# CLK3_STATCOLL_SDRAM register map
Vendor: Texas Instruments
Peripheral module from a debugger description file (folder omap4460).
Registers are 32-bit, access per field, reset 0x0 unless marked. A register's access mark holds for its fields unless they carry their own. Offsets are as the file gives them; lines under a group give offsets from that group; [hi:lo] are bit positions; {n}, {i} and the like mark numbered series; 'fields as' and 'values as' point back to an identical list; <NAME> marks a mode.

## CLK3_STATCOLL_SDRAM
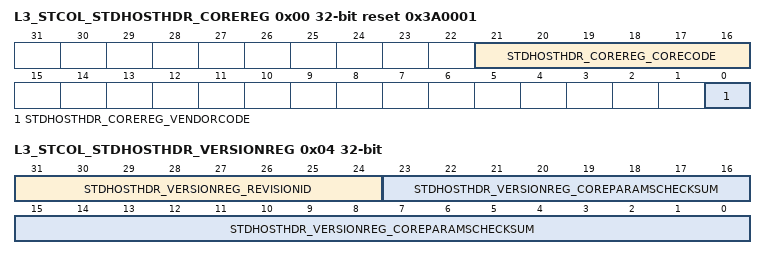
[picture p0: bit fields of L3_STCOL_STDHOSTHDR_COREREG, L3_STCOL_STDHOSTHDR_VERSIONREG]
0x00 L3_STCOL_STDHOSTHDR_COREREG ro reset 0x3A0001
  [21:16] STDHOSTHDR_COREREG_CORECODE — The Core Code field is a constant reporting a vendor-specific core generator code. Type: Constant. Reset value: 0x3A.
  [0] STDHOSTHDR_COREREG_VENDORCODE — The Vendor Code field is a constant reporting the core generator vendor code. Type: Constant. Reset value: 0x1.
    0=STDHOSTHDR_COREREG_VENDORCODE_0_r (Third-party vendor.); 1=STDHOSTHDR_COREREG_VENDORCODE_1_r
0x04 L3_STCOL_STDHOSTHDR_VERSIONREG ro
  [31:24] STDHOSTHDR_VERSIONREG_REVISIONID — The Revision Identifier field is a constant reporting the core generator revision number. Type: Constant. Reset value: 0x0.
  [23:0] STDHOSTHDR_VERSIONREG_COREPARAMSCHECKSUM — Reserved. Type: Reserved. Reset value: Reserved.
0x08 L3_STCOL_EN
  [0] EN rw — Enable performance monitoring, this will also shut down the clock if En = 0 Type: Control. Reset value: 0x0.
0x0C L3_STCOL_SOFTEN
  [0] SOFTEN rw — Software enable for performance monitoring Type: Control. Reset value: 0x0.
0x14 L3_STCOL_TRIGEN
  [0] TRIGEN rw — TrigEn when set, it enable the external trigger start and stop Type: Control. Reset value: 0x0.
0x18 L3_STCOL_REQEVT
  [3:0] REQEVT rw — Req event select Type: Control. Reset value: 0x0.
    0=Collect is disabled default value; 1=Collect all event: hit always (cycle); 2=Collect transfers: actually used cycle for transferring aN NTTP word; 3=Collect wait cycle: transfer has been delayed by source; 4=Collect busy: transfer has been delayed by destination; 5=Collect packet: new packet start; 6=Collect data: data cycle transfer, write for requests, read for responses; 7=Collect idles: transfer is not initiated by source; 8=Collect latency: hit when actually detecting debug bit on response links
0x1C L3_STCOL_RSPEVT
  [3:0] RSPEVT rw — Rsp event select Type: Control. Reset value: 0x0.
    0=Collect is disabled default value; 1=Collect all event: hit always (cycle); 2=Collect transfers: actually used cycle for transferring a NTTP word; 3=Collect wait cycle: transfer has been delayed by source; 4=Collect busy: transfer has been delayed by destination; 5=Collect packet: new packet start; 6=Collect data: data cycle transfer, write for requests, read for responses; 7=Collect idles: transfer is not initiated by source; 8=Collect latency: hit when actually detecting debug bit on response links
{0x20+4i} L3_STCOL_EVTMUX_SEL{i} (i=0..4)
  [2:0] EVTMUX_SEL{i} rw — The select of the mux {i} Type: Control. Reset value: 0x0.
0x40 L3_STCOL_DUMP_IDENTIFIER ro
  [1:0] DUMP_IDENTIFIER — Probe identifier Type: Control. Reset value: 0x0.
0x44 L3_STCOL_DUMP_COLLECTTIME
  [15:0] DUMP_COLLECTTIME rw — Number of cycle to wait between two statistics frame Type: Control. Reset value: 0x0.
0x48 L3_STCOL_DUMP_SLVADDR ro reset 0x19
  [4:0] DUMP_SLVADDR — Dump slave address Type: Control. Reset value: 0x19.
0x4C L3_STCOL_DUMP_MSTADDR ro reset 0xE0
  [7:0] DUMP_MSTADDR — Dump master address Type: Control. Reset value: 0xE0.
0x50 L3_STCOL_DUMP_SLVOFS rw reset 0x800
  [31:0] DUMP_SLVOFS — Dump slave offset Type: Control. Reset value: 0x800.
0x54 L3_STCOL_DUMP_MANUAL
  [0] DUMP_MANUAL rw — Define the dump mode: if != 0 the dump is controlled by the Send register. Type: Control. Reset value: 0x0.
0x58 L3_STCOL_DUMP_SEND
  [0] DUMP_SEND rw — In manual mode, is used to send the dump content and initialize the counters. Type: Give_AutoCleared. Reset value: 0x0.
0xAC L3_STCOL_FILTER_i_GLOBALEN
  [0] FILTER_i_GLOBALEN rw — Filter global enable Type: Control. Reset value: 0x0.
0xB0 L3_STCOL_FILTER_i_ADDRMIN
  [22:0] FILTER1_ADDRMIN rw — min addr range Type: Control. Reset value: 0x0.
0xB4 L3_STCOL_FILTER_i_ADDRMAX
  [22:0] FILTER1_ADDRMAX rw — max addr range Type: Control. Reset value: 0x0.
0xB8 L3_STCOL_FILTER_i_ADDREN
  [0] FILTER1_ADDREN rw — max filtering enable Type: Control. Reset value: 0x0.
0xBC L3_STCOL_FILTER_i_EN_k
  [0] FILTER_i_EN0 rw — Enable filter stage 0 Type: Control. Reset value: 0x0.
0xC0 L3_STCOL_FILTER_i_MASK_m_RD
  [0] FILTER_i_MASK_m_RD rw — Mask/Match of Rd Type: Control. Reset value: 0x0.
0xC4 L3_STCOL_FILTER_i_MASK_m_WR
  [0] FILTER_i_MASK_m_WR rw — Mask/Match of Wr Type: Control. Reset value: 0x0.
0xC8 L3_STCOL_FILTER_i_MASK_m_MSTADDR
  [7:0] FILTER_i_MASK_m_MSTADDR rw — Mask/Match of MstAddr Type: Control. Reset value: 0x0.
0xD0 L3_STCOL_FILTER_i_MASK_m_ERR
  [0] FILTER_i_MASK_m_ERR rw — Mask/Match of Err Type: Control. Reset value: 0x0.
0xD4 L3_STCOL_FILTER_i_MASK_m_USERINFO
  [17:0] FILTER_i_MASK_m_USERINFO rw — Mask/Match of UserInfo Type: Control. Reset value: 0x0.
0xE0 L3_STCOL_FILTER_i_MATCH_m_RD
  [0] FILTER_i_MATCH_m_RD rw — Mask/Match of Rd Type: Control. Reset value: 0x0.
0xE4 L3_STCOL_FILTER_i_MATCH_m_WR
  [0] FILTER_i_MATCH_m_WR rw — Mask/Match of Wr Type: Control. Reset value: 0x0.
0xE8 L3_STCOL_FILTER_i_MATCH_m_MSTADDR
  [7:0] FILTER_i_MATCH_m_MSTADDR rw — Mask/Match of MstAddr Type: Control. Reset value: 0x0.
0xF0 L3_STCOL_FILTER_i_MATCH_m_ERR
  [0] FILTER_i_MATCH_m_ERR rw — Mask/Match of Err Type: Control. Reset value: 0x0.
0xF4 L3_STCOL_FILTER_i_MATCH_m_USERINFO
  [17:0] FILTER_i_MATCH_m_USERINFO rw — Mask/Match of UserInfo Type: Control. Reset value: 0x0.
0x1F0 L3_STCOL_OP_i_THRESHOLD_MINVAL
  [11:0] OP_i_THRESHOLD_MINVAL rw — Min value Type: Control. Reset value: 0x0.
0x1F4 L3_STCOL_OP_i_THRESHOLD_MAXVAL
  [11:0] OP_i_THRESHOLD_MAXVAL rw — Max value Type: Control. Reset value: 0x0.
0x1F8 L3_STCOL_OP_i_EVTINFOSEL
  [1:0] OP_i_EVTINFOSEL rw — Select event info data to add to counter (len/press or latency) Type: Control. Reset value: 0x0.
    0=Select len from event info list; 1=Select pressure if available from event info list; 2=Select latency if available from event info list
0x1FC L3_STCOL_OP_i_SEL
  [3:0] OP_i_SEL rw — Select logical operation Type: Control. Reset value: 0x0.
    0=Increment counter on each mask/match filter hit; 1=Increment counter on each min/max level hit; 2=Add to counter the selected event info value (len/press or latency); 3=increment counter when all filter event hits (And(Fi)); 4=Increment counter if any of filter event hits (Or(Fi)); 5=Add to counter the number of current request event that hit; 6=Add to counter the number of current response event that hit; 7=Add to counter the number of all event that hit; 8=Increment counter on each selected external event hit
